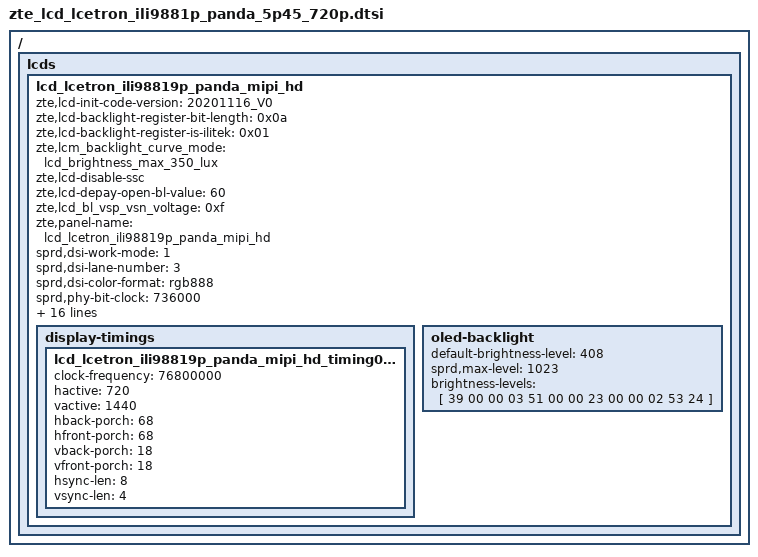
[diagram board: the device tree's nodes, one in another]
/ { lcds {
	lcd_lcetron_ili98819p_panda_mipi_hd: lcd_lcetron_ili98819p_panda_mipi_hd {
		zte,lcd-init-code-version = "20201116_V0";
		zte,lcd-backlight-register-bit-length = <0x0a>;
		zte,lcd-backlight-register-is-ilitek = <0x01>;
		zte,lcm_backlight_curve_mode = "lcd_brightness_max_350_lux";
		zte,lcd-disable-ssc;
		zte,lcd-depay-open-bl-value = <60>;
		zte,lcd_bl_vsp_vsn_voltage = <0xf>;
		zte,panel-name = "lcd_lcetron_ili98819p_panda_mipi_hd";

		sprd,dsi-work-mode = <1>; /* video burst mode*/
		sprd,dsi-lane-number = <3>;
		sprd,dsi-color-format = "rgb888";

		sprd,phy-bit-clock = <736000>;	/* kbps */
		sprd,phy-escape-clock = <20000>;/* kHz */

		sprd,width-mm = <61884>;
		sprd,height-mm = <123768>;

		sprd,esd-check-enable = <1>;/* 0:close , 1:open */
		sprd,esd-check-mode = <1>;/* 0:REG ,1:TE  */
		sprd,esd-check-period = <1000>;
		sprd,esd-check-register = <0x0A>;
		sprd,esd-check-value = <0x9C>;
		sprd,reset-on-sequence = <1 10>, <0 12>, <1 20>;
		sprd,reset-off-sequence = <0 0>, <0 0>, <1 20>;
		sprd,initial-command = [
			39 00 00 04 FF 98 81 06
			23 00 00 02 01 03
			23 00 00 02 04 01
			23 00 00 02 2B 0A
			23 00 00 02 C0 CF
			23 00 00 02 C1 2A

			39 00 00 04 FF 98 81 05
			23 00 00 02 B2 70
			23 00 00 02 03 00
			23 00 00 02 04 1E

			23 00 00 02 1B 09
			23 00 00 02 B1 70
			23 00 00 02 78 01
			23 00 00 02 A9 C0
			23 00 00 02 1E 11
			23 00 00 02 4C 11

			23 00 00 02 38 A0
			23 00 00 02 1A 50

			23 00 00 02 54 28
			23 00 00 02 55 25
			23 00 00 02 4D 22
			23 00 00 02 26 0E

			23 00 00 02 1B 01

			39 00 00 04 FF 98 81 02
			23 00 00 02 42 01
			23 00 00 02 44 01
			23 00 00 02 01 50
			23 00 00 02 15 10

			39 00 00 04 FF 98 81 01
			23 00 00 02 01 00
			23 00 00 02 02 00
			23 00 00 02 03 56
			23 00 00 02 04 13
			23 00 00 02 05 13
			23 00 00 02 06 0a
			23 00 00 02 07 05
			23 00 00 02 08 05
			23 00 00 02 09 1D
			23 00 00 02 0a 01
			23 00 00 02 0b 00
			23 00 00 02 0c 3F
			23 00 00 02 0d 29
			23 00 00 02 0e 29
			23 00 00 02 0f 1D
			23 00 00 02 10 1D
			23 00 00 02 11 00
			23 00 00 02 12 00
			23 00 00 02 13 08
			23 00 00 02 14 08
			23 00 00 02 15 00
			23 00 00 02 16 00
			23 00 00 02 17 00
			23 00 00 02 18 00
			23 00 00 02 19 00
			23 00 00 02 1a 00
			23 00 00 02 1b 00
			23 00 00 02 1c 00
			23 00 00 02 1d 00
			23 00 00 02 1e 40
			23 00 00 02 1f 88
			23 00 00 02 20 08
			23 00 00 02 21 01
			23 00 00 02 22 00
			23 00 00 02 23 00
			23 00 00 02 24 00
			23 00 00 02 25 00
			23 00 00 02 26 00
			23 00 00 02 27 00
			23 00 00 02 28 33
			23 00 00 02 29 03
			23 00 00 02 2a 00
			23 00 00 02 2b 00
			23 00 00 02 2c 00
			23 00 00 02 2d 00
			23 00 00 02 2e 00
			23 00 00 02 2f 00
			23 00 00 02 30 00
			23 00 00 02 31 00
			23 00 00 02 32 00
			23 00 00 02 33 00
			23 00 00 02 34 00
			23 00 00 02 35 00
			23 00 00 02 36 00
			23 00 00 02 37 00
			23 00 00 02 38 00
			23 00 00 02 39 0f
			23 00 00 02 3a 2a
			23 00 00 02 3b 00
			23 00 00 02 3c 00
			23 00 00 02 3d 00
			23 00 00 02 3e 00
			23 00 00 02 3f 00
			23 00 00 02 40 00
			23 00 00 02 41 e0
			23 00 00 02 42 40
			23 00 00 02 43 0f
			23 00 00 02 44 11
			23 00 00 02 45 a8
			23 00 00 02 46 00
			23 00 00 02 47 08
			23 00 00 02 48 00
			23 00 00 02 49 01
			23 00 00 02 4a 00
			23 00 00 02 4b 00

			23 00 00 02 4c b2
			23 00 00 02 4d 22
			23 00 00 02 4e 01
			23 00 00 02 4f f7
			23 00 00 02 50 29
			23 00 00 02 51 72
			23 00 00 02 52 25
			23 00 00 02 53 b2
			23 00 00 02 54 22
			23 00 00 02 55 22
			23 00 00 02 56 22

			23 00 00 02 57 a2
			23 00 00 02 58 22
			23 00 00 02 59 01
			23 00 00 02 5a e6
			23 00 00 02 5b 28
			23 00 00 02 5c 62
			23 00 00 02 5d 24
			23 00 00 02 5e a2
			23 00 00 02 5f 22
			23 00 00 02 60 22
			23 00 00 02 61 22

			23 00 00 02 62 ee

			23 00 00 02 63 02
			23 00 00 02 64 0b
			23 00 00 02 65 02
			23 00 00 02 66 02
			23 00 00 02 67 01
			23 00 00 02 68 00
			23 00 00 02 69 0f
			23 00 00 02 6a 07
			23 00 00 02 6b 55
			23 00 00 02 6c 02
			23 00 00 02 6d 02
			23 00 00 02 6e 5b
			23 00 00 02 6f 59
			23 00 00 02 70 02
			23 00 00 02 71 02
			23 00 00 02 72 57
			23 00 00 02 73 02
			23 00 00 02 74 02
			23 00 00 02 75 02
			23 00 00 02 76 02
			23 00 00 02 77 02
			23 00 00 02 78 02

			23 00 00 02 79 02
			23 00 00 02 7a 0a
			23 00 00 02 7b 02
			23 00 00 02 7c 02
			23 00 00 02 7d 01
			23 00 00 02 7e 00
			23 00 00 02 7f 0e
			23 00 00 02 80 06
			23 00 00 02 81 54
			23 00 00 02 82 02
			23 00 00 02 83 02
			23 00 00 02 84 5a
			23 00 00 02 85 58
			23 00 00 02 86 02
			23 00 00 02 87 02
			23 00 00 02 88 56
			23 00 00 02 89 02
			23 00 00 02 8a 02
			23 00 00 02 8b 02
			23 00 00 02 8c 02
			23 00 00 02 8d 02
			23 00 00 02 8e 02
			23 00 00 02 8f 44
			23 00 00 02 90 44
			39 00 00 04 FF 98 81 02
			39 00 00 15 57 00 1B 2A 14 18 2A 1E 1F 8D 1D 2A 77 1A 17 4A 1F 26 49 59 2C
			39 00 00 15 6B 00 1B 2A 14 18 2A 1E 1F 8D 1D 2A 77 1A 17 4A 1F 26 49 59 2C
			39 00 00 04 FF 98 81 03
			23 00 00 02 80 44
			23 00 00 02 81 44
			23 00 00 02 82 44
			23 00 00 02 83 40 /*10bit 2:12bit 3:11bit 4:10bit 5:9bit 6:8bit*/
			39 00 00 04 FF 98 81 00
			23 00 00 02 35 00
			23 00 00 02 36 00
			39 00 00 03 51 00 00
			23 00 00 02 53 2c
			39 00 00 02 55 00
			23 78 00 02 11 00
			23 14 00 02 29 00
			];
		sprd,sleep-in-command = [
			39 00 00 03 51 00 00
			13 19 00 01 28
			13 F0 00 01 10
			];
		sprd,sleep-out-command = [
			13 78 00 01 11
			13 64 00 01 29
			];

		display-timings {
			lcd_lcetron_ili98819p_panda_mipi_hd_timing0: timing0 {
			clock-frequency = <76800000>;
			hactive = <720>;
			vactive = <1440>;
			hback-porch = <68>;
			hfront-porch = <68>;
			vback-porch = <18>;
			vfront-porch = <18>;
			hsync-len = <8>;
			vsync-len = <4>;
			};
		};
		oled-backlight {
			default-brightness-level = <408>;
			sprd,max-level = <1023>;
			brightness-levels = [
				39 00 00 03 51 00 00
				23 00 00 02 53 24
			];
		};
	};
};};

